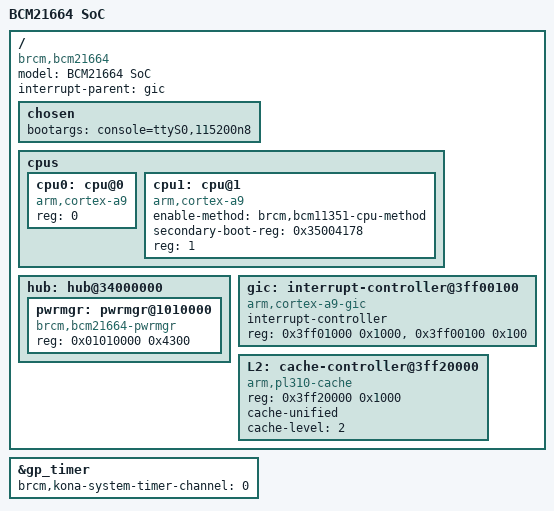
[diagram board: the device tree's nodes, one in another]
// SPDX-License-Identifier: GPL-2.0-only
// Copyright (C) 2014 Broadcom Corporation

#include "bcm21664-common.dtsi"

#include <dt-bindings/interrupt-controller/arm-gic.h>

/ {
	#address-cells = <1>;
	#size-cells = <1>;
	model = "BCM21664 SoC";
	compatible = "brcm,bcm21664";
	interrupt-parent = <&gic>;

	chosen {
		bootargs = "console=ttyS0,115200n8";
	};

	cpus {
		#address-cells = <1>;
		#size-cells = <0>;

		cpu0: cpu@0 {
			device_type = "cpu";
			compatible = "arm,cortex-a9";
			reg = <0>;
		};

		cpu1: cpu@1 {
			device_type = "cpu";
			compatible = "arm,cortex-a9";
			enable-method = "brcm,bcm11351-cpu-method";
			secondary-boot-reg = <0x35004178>;
			reg = <1>;
		};
	};

	hub: hub@34000000 {
		pwrmgr: pwrmgr@1010000 {
			compatible = "brcm,bcm21664-pwrmgr";
			reg = <0x01010000 0x4300>;
			#power-domain-cells = <1>;
		};
	};

	gic: interrupt-controller@3ff00100 {
		compatible = "arm,cortex-a9-gic";
		#interrupt-cells = <3>;
		#address-cells = <0>;
		interrupt-controller;
		reg = <0x3ff01000 0x1000>,
		      <0x3ff00100 0x100>;
	};

	L2: cache-controller@3ff20000 {
		compatible = "arm,pl310-cache";
		reg = <0x3ff20000 0x1000>;
		cache-unified;
		cache-level = <2>;
	};
};

&gp_timer {
	brcm,kona-system-timer-channel = <0>;
};
